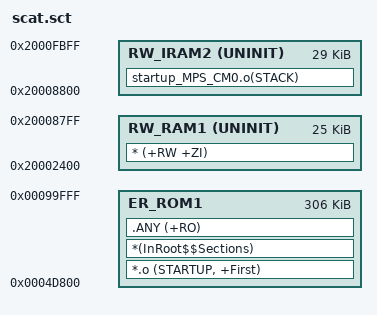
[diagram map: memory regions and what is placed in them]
; *************************************************************
; *** Scatter-Loading Description File generated by uVision ***
; *************************************************************
LR_ROM1 0x0004D800 0x4C800;0x00000100 0x000A0000			; load region size_region
{    
	ER_ROM1 0x0004D800 0x4C800;0x000A0000  				; load address = execution address
	{  
		*.o (STARTUP, +First)
		*(InRoot$$Sections)
		.ANY (+RO)
	}
	
	RW_RAM1 0x20002400 UNINIT 0x00006400;0x00006000  ; RW data
	{  
		* (+RW +ZI)
		//MAG_RAMCode.o
	}
	RW_IRAM2 0x20008800 UNINIT 0x00007400;0x00005600  
	{  
		startup_MPS_CM0.o(STACK)
	}
	;RW_IRAM3 0x20008408 UNINIT 0x0002800  ;	0x2000AC08
	;{  
      ;startup_MPS_CM0.o(HEAP)
	;}

}

